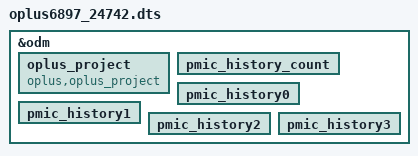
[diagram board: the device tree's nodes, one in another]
// SPDX-License-Identifier: (GPL-2.0 OR MIT)
/*
 * Copyright (C) 2022 MediaTek Inc.
 */
#include "k6897v1_64.dts"

&odm {
	oplus_project:oplus_project {
		compatible = "oplus,oplus_project";
    };
	pmic_history_count:pmic_history_count {
	};
	pmic_history0:pmic_history0 {
	};
	pmic_history1:pmic_history1 {
	};
	pmic_history2:pmic_history2 {
	};
	pmic_history3:pmic_history3 {
	};
};

/*End of this file, DO NOT ADD ANYTHING HERE*/
